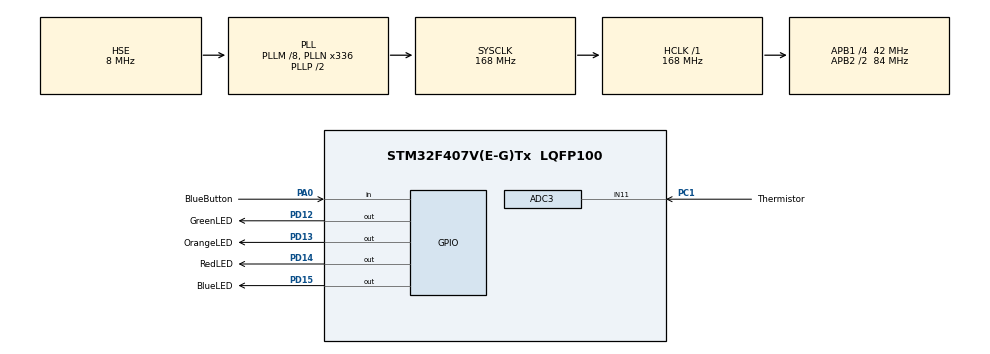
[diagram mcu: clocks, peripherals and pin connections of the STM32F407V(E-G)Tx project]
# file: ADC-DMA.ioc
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ADC1.Channel-1\#ChannelRegularConversion=ADC_CHANNEL_TEMPSENSOR
ADC1.ContinuousConvMode=ENABLE
ADC1.DMAContinuousRequests=ENABLE
ADC1.NbrOfConversionFlag=1
ADC1.Rank-1\#ChannelRegularConversion=1
ADC1.SamplingTime-1\#ChannelRegularConversion=ADC_SAMPLETIME_84CYCLES
ADC1.master=1
ADC3.Channel-1\#ChannelRegularConversion=ADC_CHANNEL_11
ADC3.ContinuousConvMode=ENABLE
ADC3.DMAContinuousRequests=ENABLE
ADC3.NbrOfConversionFlag=1
ADC3.Rank-1\#ChannelRegularConversion=1
ADC3.SamplingTime-1\#ChannelRegularConversion=ADC_SAMPLETIME_84CYCLES
Dma.ADC1.0.Direction=DMA_PERIPH_TO_MEMORY
Dma.ADC1.0.FIFOMode=DMA_FIFOMODE_DISABLE
Dma.ADC1.0.Instance=DMA2_Stream4
Dma.ADC1.0.MemDataAlignment=DMA_MDATAALIGN_WORD
Dma.ADC1.0.MemInc=DMA_MINC_ENABLE
Dma.ADC1.0.Mode=DMA_CIRCULAR
Dma.ADC1.0.PeriphDataAlignment=DMA_PDATAALIGN_WORD
Dma.ADC1.0.PeriphInc=DMA_PINC_DISABLE
Dma.ADC1.0.Priority=DMA_PRIORITY_LOW
Dma.ADC3.1.Direction=DMA_PERIPH_TO_MEMORY
Dma.ADC3.1.FIFOMode=DMA_FIFOMODE_DISABLE
Dma.ADC3.1.Instance=DMA2_Stream0
Dma.ADC3.1.MemDataAlignment=DMA_MDATAALIGN_WORD
Dma.ADC3.1.MemInc=DMA_MINC_ENABLE
Dma.ADC3.1.Mode=DMA_CIRCULAR
Dma.ADC3.1.PeriphDataAlignment=DMA_PDATAALIGN_WORD
Dma.ADC3.1.PeriphInc=DMA_PINC_DISABLE
Dma.ADC3.1.Priority=DMA_PRIORITY_LOW
Dma.Request0=ADC1
Dma.Request1=ADC3
Mcu.Family=STM32F4
Mcu.Name=STM32F407V(E-G)Tx
Mcu.Package=LQFP100
NVIC.DMA2_Stream0_IRQn=true\:0\:0\:false\:false\:true\:false\:true
NVIC.DMA2_Stream4_IRQn=true\:0\:0\:false\:false\:true\:false\:true
NVIC.PriorityGroup=NVIC_PRIORITYGROUP_4
PA0-WKUP.GPIO_Label=BlueButton
PA0-WKUP.Signal=GPIO_Input
PA13.Mode=Trace_Asynchronous_SW
PA13.Signal=SYS_JTMS-SWDIO
PA14.Mode=Trace_Asynchronous_SW
PA14.Signal=SYS_JTCK-SWCLK
PB3.Mode=Trace_Asynchronous_SW
PB3.Signal=SYS_JTDO-SWO
PC1.GPIO_Label=Thermistor
PC1.Signal=ADCx_IN11
PD12.GPIO_Label=GreenLED
PD12.Signal=GPIO_Output
PD13.GPIO_Label=OrangeLED
PD13.Signal=GPIO_Output
PD14.GPIO_Label=RedLED
PD14.Signal=GPIO_Output
PD15.GPIO_Label=BlueLED
PD15.Signal=GPIO_Output
PH0-OSC_IN.Mode=HSE-External-Oscillator
PH0-OSC_IN.Signal=RCC_OSC_IN
PH1-OSC_OUT.Mode=HSE-External-Oscillator
PH1-OSC_OUT.Signal=RCC_OSC_OUT
ProjectManager.HeapSize=0x200
ProjectManager.StackSize=0x400
ProjectManager.TargetToolchain=STM32CubeIDE
RCC.48MHZClocksFreq_Value=48000000
RCC.AHBFreq_Value=168000000
RCC.APB1CLKDivider=RCC_HCLK_DIV4
RCC.APB1Freq_Value=42000000
RCC.APB1TimFreq_Value=84000000
RCC.APB2CLKDivider=RCC_HCLK_DIV2
RCC.APB2Freq_Value=84000000
RCC.APB2TimFreq_Value=168000000
RCC.CortexFreq_Value=168000000
RCC.HCLKFreq_Value=168000000
RCC.HSE_VALUE=8000000
RCC.HSI_VALUE=16000000
RCC.LSE_VALUE=32768
RCC.PLLM=8
RCC.PLLN=336
RCC.PLLQ=7
RCC.PLLSourceVirtual=RCC_PLLSOURCE_HSE
RCC.SYSCLKFreq_VALUE=168000000
RCC.SYSCLKSource=RCC_SYSCLKSOURCE_PLLCLK
RCC.VCOOutputFreq_Value=336000000
SH.ADCx_IN11.0=ADC3_IN11,IN11
VP_ADC1_TempSens_Input.Mode=IN-TempSens
VP_RNG_VS_RNG.Mode=RNG_Activate
board=custom

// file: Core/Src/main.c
/* USER CODE BEGIN Header */
/**
  ******************************************************************************
  * @file           : main.c
  * @brief          : Main program body
  * *@Author         : Ganyun Huang
  * @Student ID     : C0356275
  * @LAB Name       : ADC-DMA-Lab
  ******************************************************************************
  * @attention
  *
  * <h2><center>&copy; Copyright (c) 2020 STMicroelectronics.
  * All rights reserved.</center></h2>
  *
  * This software component is licensed by ST under BSD 3-Clause license,
  * the "License"; You may not use this file except in compliance with the
  * License. You may obtain a copy of the License at:
  *                        opensource.org/licenses/BSD-3-Clause
  *
  ******************************************************************************
  */
/* USER CODE END Header */
#include "main.h"
#include "stdio.h"

ADC_HandleTypeDef hadc1;
ADC_HandleTypeDef hadc3;
DMA_HandleTypeDef hdma_adc1;
DMA_HandleTypeDef hdma_adc3;

RNG_HandleTypeDef hrng;

void SystemClock_Config(void);
static void MX_GPIO_Init(void);
static void MX_DMA_Init(void);
static void MX_RNG_Init(void);
static void MX_ADC1_Init(void);
static void MX_ADC3_Init(void);
/* USER CODE BEGIN PFP */
uint32_t thermArray[100];      //100 Samples
uint32_t thermValue;           //Thermistor value
uint32_t dieArray[100];
uint32_t dieValue;
//float A;                       //Average value of 100 samples
//float DA;
float T;					   //Temperature of thermistor
float DT;
/* USER CODE END PFP */

int main(void)
{

  /* MCU Configuration--------------------------------------------------------*/

  /* Reset of all peripherals, Initializes the Flash interface and the Systick. */
  HAL_Init();

  /* Configure the system clock */
  SystemClock_Config();

  /* Initialize all configured peripherals */
  MX_GPIO_Init();
  MX_DMA_Init();
  MX_RNG_Init();
  MX_ADC1_Init();
  MX_ADC3_Init();
  /* USER CODE BEGIN 2 */
  HAL_ADC_Start_DMA(&hadc3, thermArray, 100);  //Use DMA to read ADC1 and ADC3
  HAL_ADC_Start_DMA(&hadc1, dieArray, 100);
  /* USER CODE END 2 */

  /* Infinite loop */
  while (1)
  {
	  HAL_GPIO_WritePin (OrangeLED_GPIO_Port, OrangeLED_Pin, GPIO_PIN_SET);
	 HAL_Delay(250);
	  HAL_GPIO_WritePin (OrangeLED_GPIO_Port, OrangeLED_Pin, GPIO_PIN_RESET); // ON/OFF Orange Light
	  HAL_Delay(250);

	  	 for (int i=0; i< 100; i++)																	//take 100 sample value first
	  		thermValue += thermArray[i]  ;
	  	   HAL_Delay(10);

	  	   thermValue /=100;
	  	 // A = 0;																						//Calculate the average of all samples
	  	  // for(int i=0; i<100; i++)
	  	 // A += thermArray[i];
	  	 // A /= 100;

	  	  printf("value: %1i\n", thermValue);																	//Output the Value of thermistor

	  	   T =(1/((log(((10000.0*thermValue)/(4095.0 - thermValue))/100000.0)/3950.0)+(1/(273.15 + 25.000))))- 273.15;	//Calculate the temperature

	  	  printf("Temperature: %0.1f\n",T);

	  	  for (int j=0; j< 100; j++)																	//take 100 sample value first
	  		dieValue += dieArray[j] ;
	  	  HAL_Delay(10);

	  	  dieValue /= 100;

	  	 //DA = 0;																						//Calculate the average of all samples
	  	 //for(int j=0; j<100; j++)
	  	 //DA += dieArray[j];
	     //DA /= 100;
	  	//printf("Dievalue: %1f\n", DA );
	  	DT = (dieValue/4095.0*3.00 - 0.76)/0.0025 +25;     //Calculate the die temperature and print it
	   printf("DieTemperature: %0.1f\n",DT);
  }
}

void SystemClock_Config(void)
{
  RCC_OscInitTypeDef RCC_OscInitStruct = {0};
  RCC_ClkInitTypeDef RCC_ClkInitStruct = {0};

  /** Configure the main internal regulator output voltage
  */
  __HAL_RCC_PWR_CLK_ENABLE();
  __HAL_PWR_VOLTAGESCALING_CONFIG(PWR_REGULATOR_VOLTAGE_SCALE1);
  /** Initializes the RCC Oscillators according to the specified parameters
  * in the RCC_OscInitTypeDef structure.
  */
  RCC_OscInitStruct.OscillatorType = RCC_OSCILLATORTYPE_HSE;
  RCC_OscInitStruct.HSEState = RCC_HSE_ON;
  RCC_OscInitStruct.PLL.PLLState = RCC_PLL_ON;
  RCC_OscInitStruct.PLL.PLLSource = RCC_PLLSOURCE_HSE;
  RCC_OscInitStruct.PLL.PLLM = 8;
  RCC_OscInitStruct.PLL.PLLN = 336;
  RCC_OscInitStruct.PLL.PLLP = RCC_PLLP_DIV2;
  RCC_OscInitStruct.PLL.PLLQ = 7;
  if (HAL_RCC_OscConfig(&RCC_OscInitStruct) != HAL_OK)
  {
    Error_Handler();
  }
  /** Initializes the CPU, AHB and APB buses clocks
  */
  RCC_ClkInitStruct.ClockType = RCC_CLOCKTYPE_HCLK|RCC_CLOCKTYPE_SYSCLK
                              |RCC_CLOCKTYPE_PCLK1|RCC_CLOCKTYPE_PCLK2;
  RCC_ClkInitStruct.SYSCLKSource = RCC_SYSCLKSOURCE_PLLCLK;
  RCC_ClkInitStruct.AHBCLKDivider = RCC_SYSCLK_DIV1;
  RCC_ClkInitStruct.APB1CLKDivider = RCC_HCLK_DIV4;
  RCC_ClkInitStruct.APB2CLKDivider = RCC_HCLK_DIV2;

  if (HAL_RCC_ClockConfig(&RCC_ClkInitStruct, FLASH_LATENCY_5) != HAL_OK)
  {
    Error_Handler();
  }
}

static void MX_ADC1_Init(void)
{

  ADC_ChannelConfTypeDef sConfig = {0};

  /** Configure the global features of the ADC (Clock, Resolution, Data Alignment and number of conversion)
  */
  hadc1.Instance = ADC1;
  hadc1.Init.ClockPrescaler = ADC_CLOCK_SYNC_PCLK_DIV4;
  hadc1.Init.Resolution = ADC_RESOLUTION_12B;
  hadc1.Init.ScanConvMode = DISABLE;
  hadc1.Init.ContinuousConvMode = ENABLE;
  hadc1.Init.DiscontinuousConvMode = DISABLE;
  hadc1.Init.ExternalTrigConvEdge = ADC_EXTERNALTRIGCONVEDGE_NONE;
  hadc1.Init.ExternalTrigConv = ADC_SOFTWARE_START;
  hadc1.Init.DataAlign = ADC_DATAALIGN_RIGHT;
  hadc1.Init.NbrOfConversion = 1;
  hadc1.Init.DMAContinuousRequests = ENABLE;
  hadc1.Init.EOCSelection = ADC_EOC_SINGLE_CONV;
  if (HAL_ADC_Init(&hadc1) != HAL_OK)
  {
    Error_Handler();
  }
  /** Configure for the selected ADC regular channel its corresponding rank in the sequencer and its sample time.
  */
  sConfig.Channel = ADC_CHANNEL_TEMPSENSOR;
  sConfig.Rank = 1;
  sConfig.SamplingTime = ADC_SAMPLETIME_84CYCLES;
  if (HAL_ADC_ConfigChannel(&hadc1, &sConfig) != HAL_OK)
  {
    Error_Handler();
  }

}

static void MX_ADC3_Init(void)
{

  ADC_ChannelConfTypeDef sConfig = {0};

  /** Configure the global features of the ADC (Clock, Resolution, Data Alignment and number of conversion)
  */
  hadc3.Instance = ADC3;
  hadc3.Init.ClockPrescaler = ADC_CLOCK_SYNC_PCLK_DIV4;
  hadc3.Init.Resolution = ADC_RESOLUTION_12B;
  hadc3.Init.ScanConvMode = DISABLE;
  hadc3.Init.ContinuousConvMode = ENABLE;
  hadc3.Init.DiscontinuousConvMode = DISABLE;
  hadc3.Init.ExternalTrigConvEdge = ADC_EXTERNALTRIGCONVEDGE_NONE;
  hadc3.Init.ExternalTrigConv = ADC_SOFTWARE_START;
  hadc3.Init.DataAlign = ADC_DATAALIGN_RIGHT;
  hadc3.Init.NbrOfConversion = 1;
  hadc3.Init.DMAContinuousRequests = ENABLE;
  hadc3.Init.EOCSelection = ADC_EOC_SINGLE_CONV;
  if (HAL_ADC_Init(&hadc3) != HAL_OK)
  {
    Error_Handler();
  }
  /** Configure for the selected ADC regular channel its corresponding rank in the sequencer and its sample time.
  */
  sConfig.Channel = ADC_CHANNEL_11;
  sConfig.Rank = 1;
  sConfig.SamplingTime = ADC_SAMPLETIME_84CYCLES;
  if (HAL_ADC_ConfigChannel(&hadc3, &sConfig) != HAL_OK)
  {
    Error_Handler();
  }

}

static void MX_RNG_Init(void)
{

  hrng.Instance = RNG;
  if (HAL_RNG_Init(&hrng) != HAL_OK)
  {
    Error_Handler();
  }

}

static void MX_DMA_Init(void)
{

  /* DMA controller clock enable */
  __HAL_RCC_DMA2_CLK_ENABLE();

  /* DMA interrupt init */
  /* DMA2_Stream0_IRQn interrupt configuration */
  HAL_NVIC_SetPriority(DMA2_Stream0_IRQn, 0, 0);
  HAL_NVIC_EnableIRQ(DMA2_Stream0_IRQn);
  /* DMA2_Stream4_IRQn interrupt configuration */
  HAL_NVIC_SetPriority(DMA2_Stream4_IRQn, 0, 0);
  HAL_NVIC_EnableIRQ(DMA2_Stream4_IRQn);

}

static void MX_GPIO_Init(void)
{
  GPIO_InitTypeDef GPIO_InitStruct = {0};

  /* GPIO Ports Clock Enable */
  __HAL_RCC_GPIOH_CLK_ENABLE();
  __HAL_RCC_GPIOC_CLK_ENABLE();
  __HAL_RCC_GPIOA_CLK_ENABLE();
  __HAL_RCC_GPIOD_CLK_ENABLE();
  __HAL_RCC_GPIOB_CLK_ENABLE();

  /*Configure GPIO pin Output Level */
  HAL_GPIO_WritePin(GPIOD, GreenLED_Pin|OrangeLED_Pin|RedLED_Pin|BlueLED_Pin, GPIO_PIN_RESET);

  /*Configure GPIO pin : BlueButton_Pin */
  GPIO_InitStruct.Pin = BlueButton_Pin;
  GPIO_InitStruct.Mode = GPIO_MODE_INPUT;
  GPIO_InitStruct.Pull = GPIO_NOPULL;
  HAL_GPIO_Init(BlueButton_GPIO_Port, &GPIO_InitStruct);

  /*Configure GPIO pins : GreenLED_Pin OrangeLED_Pin RedLED_Pin BlueLED_Pin */
  GPIO_InitStruct.Pin = GreenLED_Pin|OrangeLED_Pin|RedLED_Pin|BlueLED_Pin;
  GPIO_InitStruct.Mode = GPIO_MODE_OUTPUT_PP;
  GPIO_InitStruct.Pull = GPIO_NOPULL;
  GPIO_InitStruct.Speed = GPIO_SPEED_FREQ_LOW;
  HAL_GPIO_Init(GPIOD, &GPIO_InitStruct);

}

/* USER CODE BEGIN 4 */
int __io_putchar(int ch)
{
	ITM_SendChar(ch);
	return 0;
	}
/* USER CODE END 4 */

void Error_Handler(void)
{
}

/************************ (C) COPYRIGHT STMicroelectronics *****END OF FILE****/
